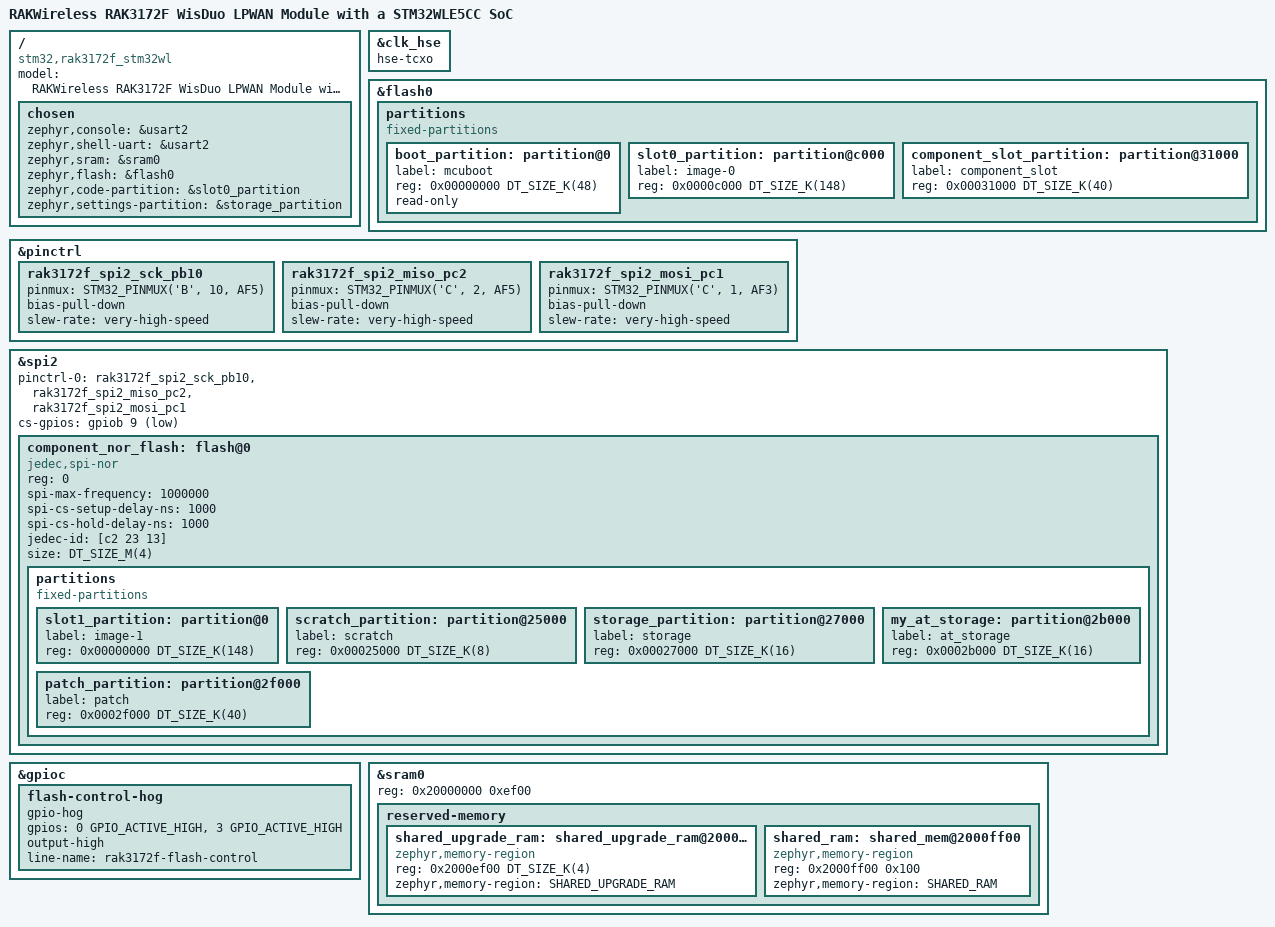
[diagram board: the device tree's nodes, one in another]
/ {
	model = "RAKWireless RAK3172F WisDuo LPWAN Module with a STM32WLE5CC SoC";
	compatible = "stm32,rak3172f_stm32wl";

	chosen {
		zephyr,console = &usart2;
		zephyr,shell-uart = &usart2;
		zephyr,sram = &sram0;
		zephyr,flash = &flash0;
		zephyr,code-partition = &slot0_partition;
		zephyr,settings-partition = &storage_partition;
	};
};

&clk_hse {
	hse-tcxo;
};

&flash0 {
	partitions {
		compatible = "fixed-partitions";
		#address-cells = <1>;
		#size-cells = <1>;
	/delete-node/ partition@0;
	/delete-node/ partition@8000;
	/delete-node/ partition@23000;
	/delete-node/ partition@34000;
	/delete-node/ partition@3e000;

		boot_partition: partition@0 {
			label = "mcuboot";
			reg = <0x00000000 DT_SIZE_K(48)>;
			read-only;
		};

	slot0_partition: partition@c000 {
		label = "image-0";
		reg = <0x0000c000 DT_SIZE_K(148)>;
	};

	component_slot_partition: partition@31000 {
		label = "component_slot";
		reg = <0x00031000 DT_SIZE_K(40)>;
	};
	};
};

&pinctrl {
	rak3172f_spi2_sck_pb10: rak3172f_spi2_sck_pb10 {
		pinmux = <STM32_PINMUX('B', 10, AF5)>;
		bias-pull-down;
		slew-rate = "very-high-speed";
	};

	rak3172f_spi2_miso_pc2: rak3172f_spi2_miso_pc2 {
		pinmux = <STM32_PINMUX('C', 2, AF5)>;
		bias-pull-down;
		slew-rate = "very-high-speed";
	};

	rak3172f_spi2_mosi_pc1: rak3172f_spi2_mosi_pc1 {
		pinmux = <STM32_PINMUX('C', 1, AF3)>;
		bias-pull-down;
		slew-rate = "very-high-speed";
	};
};

&spi2 {
	pinctrl-0 = <&rak3172f_spi2_sck_pb10 &rak3172f_spi2_miso_pc2
		     &rak3172f_spi2_mosi_pc1>;
	pinctrl-names = "default";
	cs-gpios = <&gpiob 9 GPIO_ACTIVE_LOW>;
	status = "okay";

	component_nor_flash: flash@0 {
		compatible = "jedec,spi-nor";
		reg = <0>;
		spi-max-frequency = <1000000>;
		spi-cs-setup-delay-ns = <1000>;
		spi-cs-hold-delay-ns = <1000>;
		jedec-id = [c2 23 13];
		size = <DT_SIZE_M(4)>;
		status = "okay";

		partitions {
			compatible = "fixed-partitions";
			#address-cells = <1>;
			#size-cells = <1>;

			slot1_partition: partition@0 {
				label = "image-1";
				reg = <0x00000000 DT_SIZE_K(148)>;
			};

			scratch_partition: partition@25000 {
				label = "scratch";
				reg = <0x00025000 DT_SIZE_K(8)>;
			};

			storage_partition: partition@27000 {
				label = "storage";
				reg = <0x00027000 DT_SIZE_K(16)>;
			};

			my_at_storage: partition@2b000 {
				label = "at_storage";
				reg = <0x0002b000 DT_SIZE_K(16)>;
			};

			patch_partition: partition@2f000 {
				label = "patch";
				reg = <0x0002f000 DT_SIZE_K(40)>;
			};
		};
	};
};

&gpioc {
	flash-control-hog {
		gpio-hog;
		gpios = <0 GPIO_ACTIVE_HIGH>, <3 GPIO_ACTIVE_HIGH>;
		output-high;
		line-name = "rak3172f-flash-control";
	};
};

&sram0 {
	reg = <0x20000000 0xef00>;

	reserved-memory {
		#address-cells = <1>;
		#size-cells = <1>;
		ranges;

		shared_upgrade_ram: shared_upgrade_ram@2000ef00 {
			compatible = "zephyr,memory-region";
			reg = <0x2000ef00 DT_SIZE_K(4)>;
			zephyr,memory-region = "SHARED_UPGRADE_RAM";
		};

		shared_ram: shared_mem@2000ff00 {
			compatible = "zephyr,memory-region";
			reg = <0x2000ff00 0x100>;
			zephyr,memory-region = "SHARED_RAM";
		};
	};
};
